# SMS_TIFS_CBASS_0_CBASS_FW_45080000h register map
Vendor: Texas Instruments
Peripheral module from a debugger description file (folder AM275x).
Registers are 32-bit, read-write, reset 0x0 unless marked. A register's access mark holds for its fields unless they carry their own. Offsets are as the file gives them; lines under a group give offsets from that group; [hi:lo] are bit positions; {n}, {i} and the like mark numbered series; 'fields as' and 'values as' point back to an identical list; <NAME> marks a mode.

## cbass_fw
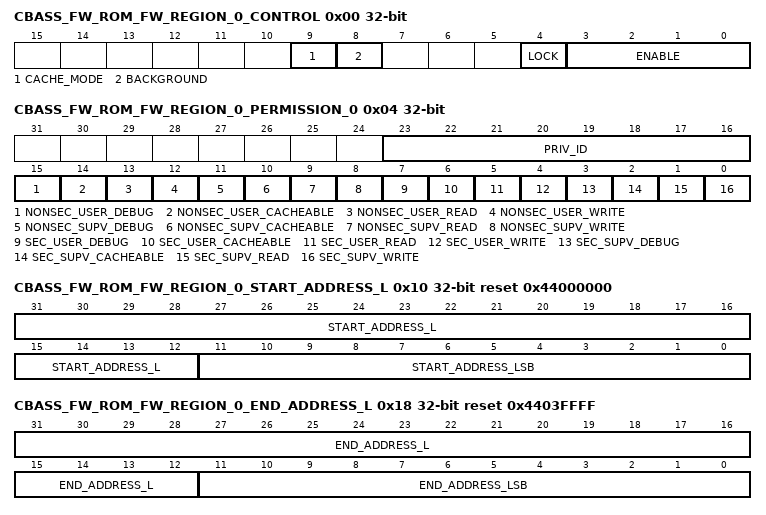
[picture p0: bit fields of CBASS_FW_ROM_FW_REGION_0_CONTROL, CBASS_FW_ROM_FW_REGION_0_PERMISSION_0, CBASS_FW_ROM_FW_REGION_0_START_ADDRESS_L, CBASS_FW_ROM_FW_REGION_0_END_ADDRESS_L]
0x00 CBASS_FW_ROM_FW_REGION_0_CONTROL access not given — The FW Region 0 Control Register defines the control fields for the target Irom.slv region 0 firewall.
  [9] CACHE_MODE rw — Cache mode for region. Set to 1 to check cache permissions. Set to 0 to ignore cache permissions. Reset Source: sms_custom_rst_mod_g_rst_n
  [8] BACKGROUND rw — Background enable for region. There can be 1 backgroun region per FW and foreground regions can have overlapping addresses only with the background region. Reset Source: sms_custom_rst_mod_g_rst_n
  [4] LOCK — Lock region. Once set region values cannot be modified. Reset Source: sms_custom_rst_mod_g_rst_n (access R/W1TS)
  [3:0] ENABLE rw — Enable region. A value of 0xA enables, others disable. Reset Source: sms_custom_rst_mod_g_rst_n
0x04 CBASS_FW_ROM_FW_REGION_0_PERMISSION_0 — The FW Region 0 Permission 0 Register defines the permissions for the target Irom.slv region 0 firewall.
  [23:16] PRIV_ID — Allowed privid. Reset Source: sms_custom_rst_mod_g_rst_n
  [15] NONSEC_USER_DEBUG — Non-secure user debug allowed. Reset Source: sms_custom_rst_mod_g_rst_n
  [14] NONSEC_USER_CACHEABLE — Non-secure user cacheable allowed. Reset Source: sms_custom_rst_mod_g_rst_n
  [13] NONSEC_USER_READ — Non-secure user read allowed. Reset Source: sms_custom_rst_mod_g_rst_n
  [12] NONSEC_USER_WRITE — Non-secure user write allowed. Reset Source: sms_custom_rst_mod_g_rst_n
  [11] NONSEC_SUPV_DEBUG — Non-secure supervisor debug allowed. Reset Source: sms_custom_rst_mod_g_rst_n
  [10] NONSEC_SUPV_CACHEABLE — Non-secure supervisor cacheable allowed. Reset Source: sms_custom_rst_mod_g_rst_n
  [9] NONSEC_SUPV_READ — Non-secure supervisor read allowed. Reset Source: sms_custom_rst_mod_g_rst_n
  [8] NONSEC_SUPV_WRITE — Non-secure supervisor write allowed. Reset Source: sms_custom_rst_mod_g_rst_n
  [7] SEC_USER_DEBUG — Secure user debug allowed. Reset Source: sms_custom_rst_mod_g_rst_n
  [6] SEC_USER_CACHEABLE — Secure user cacheable allowed. Reset Source: sms_custom_rst_mod_g_rst_n
  [5] SEC_USER_READ — Secure user read allowed. Reset Source: sms_custom_rst_mod_g_rst_n
  [4] SEC_USER_WRITE — Secure user write allowed. Reset Source: sms_custom_rst_mod_g_rst_n
  [3] SEC_SUPV_DEBUG — Secure supervisor debug allowed. Reset Source: sms_custom_rst_mod_g_rst_n
  [2] SEC_SUPV_CACHEABLE — Secure supervisor cacheable allowed. Reset Source: sms_custom_rst_mod_g_rst_n
  [1] SEC_SUPV_READ — Secure supervisor read allowed. Reset Source: sms_custom_rst_mod_g_rst_n
  [0] SEC_SUPV_WRITE — Secure supervisor write allowed. Reset Source: sms_custom_rst_mod_g_rst_n
0x10 CBASS_FW_ROM_FW_REGION_0_START_ADDRESS_L access per field reset 0x44000000 — The FW Region 0 Start Address Low Register defines the start address bits 31 to 0 for the target Irom.slv region 0 firewall.
  [31:12] START_ADDRESS_L rw — Start address bits 31 to 12. Lowest 12 bits are forced to 0 as address must be 4KB aligned. Reset Source: sms_custom_rst_mod_g_rst_n
  [11:0] START_ADDRESS_LSB ro — Start address bits 11 to 0 are forced to 0 as address must be 4KB aligned. Reset Source: sms_custom_rst_mod_g_rst_n
0x14 CBASS_FW_ROM_FW_REGION_0_START_ADDRESS_H — The FW Region 0 Start Address High Register defines the start address bits 47 to 32 for the target Irom.slv region 0 firewall.
  [15:0] START_ADDRESS_H — Start address bits 47 to 32. Reset Source: sms_custom_rst_mod_g_rst_n
0x18 CBASS_FW_ROM_FW_REGION_0_END_ADDRESS_L access per field reset 0x4403FFFF — The FW Region 0 End Address Low Register defines the end address bits 31 to 0 to include for the target Irom.slv region 0 firewall.
  [31:12] END_ADDRESS_L rw — End address bits 31 to 12 to include in the match. Lowest 12 bits are forced to 1s as address must be 4KB aligned. Reset Source: sms_custom_rst_mod_g_rst_n
  [11:0] END_ADDRESS_LSB ro — End address bits 11 to 0 are forced to 1s as address must be 4KB aligned minus 1. Reset Source: sms_custom_rst_mod_g_rst_n
0x1C CBASS_FW_ROM_FW_REGION_0_END_ADDRESS_H — The FW Region 0 End Address High Register defines the end address bits 47 to 32 to include for the target Irom.slv region 0 firewall.
  [15:0] END_ADDRESS_H — End address bits 47 to 32 to include in the match. Reset Source: sms_custom_rst_mod_g_rst_n
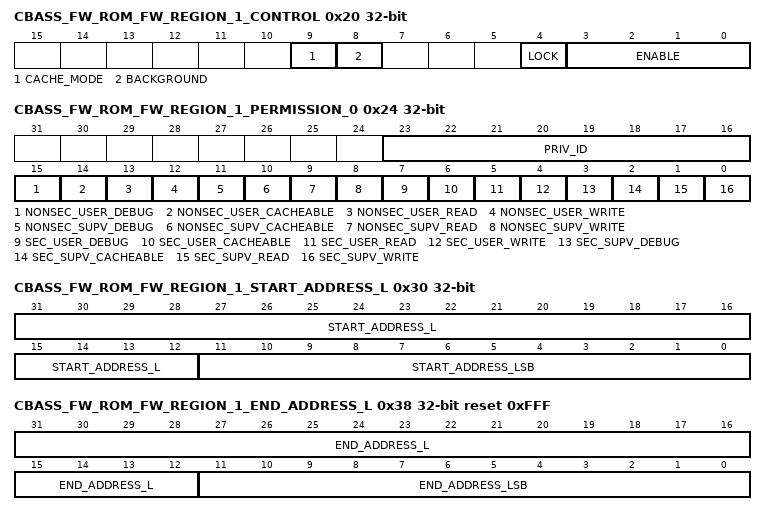
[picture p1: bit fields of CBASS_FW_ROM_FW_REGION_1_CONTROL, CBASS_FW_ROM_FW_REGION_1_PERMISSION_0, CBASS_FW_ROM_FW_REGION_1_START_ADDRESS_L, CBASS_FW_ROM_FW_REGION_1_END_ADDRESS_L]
0x20 CBASS_FW_ROM_FW_REGION_1_CONTROL access not given — The FW Region 1 Control Register defines the control fields for the target Irom.slv region 1 firewall.
  fields as CBASS_FW_ROM_FW_REGION_0_CONTROL
0x24 CBASS_FW_ROM_FW_REGION_1_PERMISSION_0 — The FW Region 1 Permission 0 Register defines the permissions for the target Irom.slv region 1 firewall.
  fields as CBASS_FW_ROM_FW_REGION_0_PERMISSION_0
0x30 CBASS_FW_ROM_FW_REGION_1_START_ADDRESS_L access per field — The FW Region 1 Start Address Low Register defines the start address bits 31 to 0 for the target Irom.slv region 1 firewall.
  fields as CBASS_FW_ROM_FW_REGION_0_START_ADDRESS_L
0x34 CBASS_FW_ROM_FW_REGION_1_START_ADDRESS_H — The FW Region 1 Start Address High Register defines the start address bits 47 to 32 for the target Irom.slv region 1 firewall.
  fields as CBASS_FW_ROM_FW_REGION_0_START_ADDRESS_H
0x38 CBASS_FW_ROM_FW_REGION_1_END_ADDRESS_L access per field reset 0xFFF — The FW Region 1 End Address Low Register defines the end address bits 31 to 0 to include for the target Irom.slv region 1 firewall.
  fields as CBASS_FW_ROM_FW_REGION_0_END_ADDRESS_L
0x3C CBASS_FW_ROM_FW_REGION_1_END_ADDRESS_H — The FW Region 1 End Address High Register defines the end address bits 47 to 32 to include for the target Irom.slv region 1 firewall.
  fields as CBASS_FW_ROM_FW_REGION_0_END_ADDRESS_H
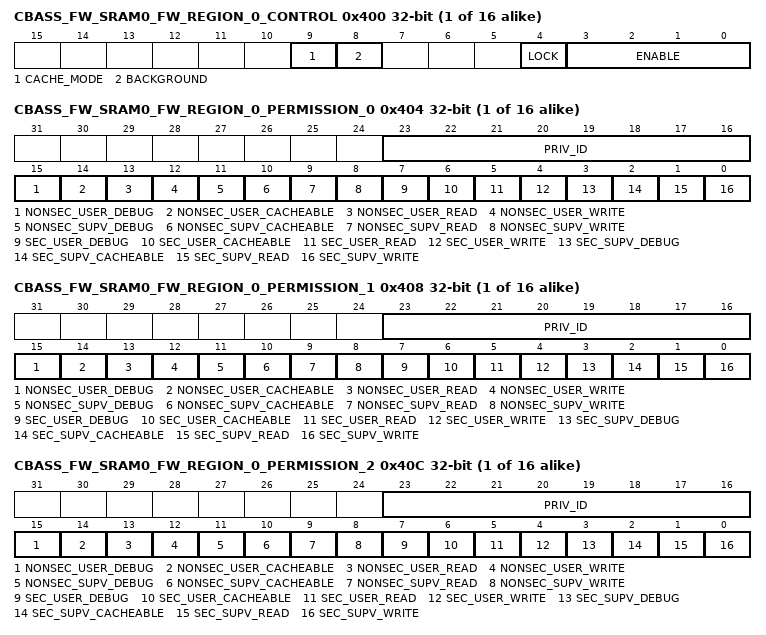
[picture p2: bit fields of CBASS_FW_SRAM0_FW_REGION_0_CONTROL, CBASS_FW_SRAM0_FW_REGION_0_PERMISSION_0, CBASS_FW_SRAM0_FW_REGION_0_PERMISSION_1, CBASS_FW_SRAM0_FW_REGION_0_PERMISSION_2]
{0x400+0x20*i} CBASS_FW_SRAM0_FW_REGION_{i}_CONTROL access not given (i=0..15) — The FW Region {i} Control Register defines the control fields for the target Isram0.slv region {i} firewall.
  fields as CBASS_FW_ROM_FW_REGION_0_CONTROL
{0x404+0x20*i} CBASS_FW_SRAM0_FW_REGION_{i}_PERMISSION_0 (i=0..15) — The FW Region {i} Permission 0 Register defines the permissions for the target Isram0.slv region {i} firewall.
  fields as CBASS_FW_ROM_FW_REGION_0_PERMISSION_0
{0x408+0x20*i} CBASS_FW_SRAM0_FW_REGION_{i}_PERMISSION_1 (i=0..15) — The FW Region {i} Permission 1 Register defines the permissions for the target Isram0.slv region {i} firewall.
  fields as CBASS_FW_ROM_FW_REGION_0_PERMISSION_0
{0x40C+0x20*i} CBASS_FW_SRAM0_FW_REGION_{i}_PERMISSION_2 (i=0..15) — The FW Region {i} Permission 2 Register defines the permissions for the target Isram0.slv region {i} firewall.
  fields as CBASS_FW_ROM_FW_REGION_0_PERMISSION_0
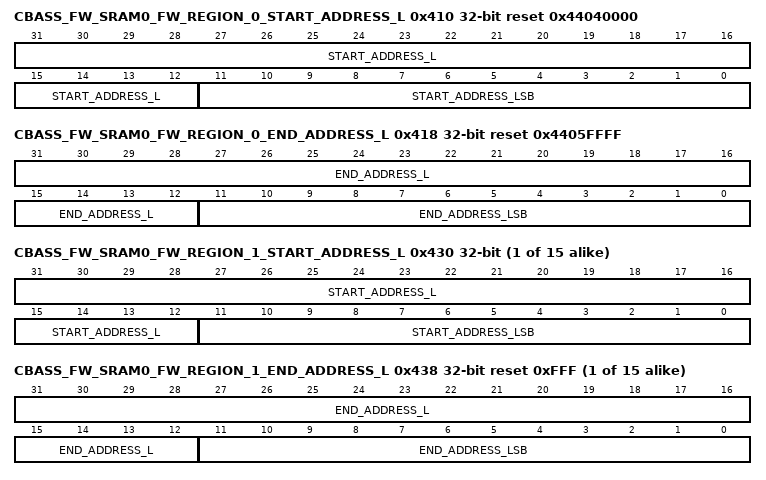
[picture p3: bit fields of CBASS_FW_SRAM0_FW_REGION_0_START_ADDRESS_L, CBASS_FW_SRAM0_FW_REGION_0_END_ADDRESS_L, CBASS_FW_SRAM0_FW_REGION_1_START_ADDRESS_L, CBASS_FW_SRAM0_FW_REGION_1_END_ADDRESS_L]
0x410 CBASS_FW_SRAM0_FW_REGION_0_START_ADDRESS_L access per field reset 0x44040000 — The FW Region 0 Start Address Low Register defines the start address bits 31 to 0 for the target Isram0.slv region 0 firewall.
  fields as CBASS_FW_ROM_FW_REGION_0_START_ADDRESS_L
{0x414+0x20*i} CBASS_FW_SRAM0_FW_REGION_{i}_START_ADDRESS_H (i=0..15) — The FW Region {i} Start Address High Register defines the start address bits 47 to 32 for the target Isram0.slv region {i} firewall.
  fields as CBASS_FW_ROM_FW_REGION_0_START_ADDRESS_H
0x418 CBASS_FW_SRAM0_FW_REGION_0_END_ADDRESS_L access per field reset 0x4405FFFF — The FW Region 0 End Address Low Register defines the end address bits 31 to 0 to include for the target Isram0.slv region 0 firewall.
  fields as CBASS_FW_ROM_FW_REGION_0_END_ADDRESS_L
{0x41C+0x20*i} CBASS_FW_SRAM0_FW_REGION_{i}_END_ADDRESS_H (i=0..15) — The FW Region {i} End Address High Register defines the end address bits 47 to 32 to include for the target Isram0.slv region {i} firewall.
  fields as CBASS_FW_ROM_FW_REGION_0_END_ADDRESS_H
{0x410+0x20*i} CBASS_FW_SRAM0_FW_REGION_{i}_START_ADDRESS_L access per field (i=1..15) — The FW Region {i} Start Address Low Register defines the start address bits 31 to 0 for the target Isram0.slv region {i} firewall.
  fields as CBASS_FW_ROM_FW_REGION_0_START_ADDRESS_L
{0x418+0x20*i} CBASS_FW_SRAM0_FW_REGION_{i}_END_ADDRESS_L access per field reset 0xFFF (i=1..15) — The FW Region {i} End Address Low Register defines the end address bits 31 to 0 to include for the target Isram0.slv region {i} firewall.
  fields as CBASS_FW_ROM_FW_REGION_0_END_ADDRESS_L
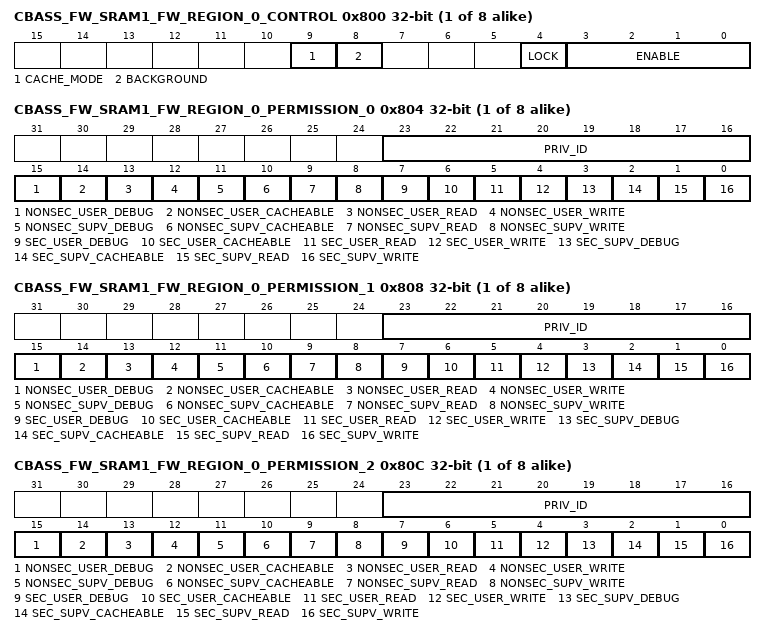
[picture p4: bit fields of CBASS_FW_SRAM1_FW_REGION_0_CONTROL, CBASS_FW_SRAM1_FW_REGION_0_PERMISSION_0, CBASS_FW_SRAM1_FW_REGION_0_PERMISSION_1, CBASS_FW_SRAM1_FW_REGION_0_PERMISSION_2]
{0x800+0x20*i} CBASS_FW_SRAM1_FW_REGION_{i}_CONTROL access not given (i=0..7) — The FW Region {i} Control Register defines the control fields for the target Isram1.slv region {i} firewall.
  fields as CBASS_FW_ROM_FW_REGION_0_CONTROL
{0x804+0x20*i} CBASS_FW_SRAM1_FW_REGION_{i}_PERMISSION_0 (i=0..7) — The FW Region {i} Permission 0 Register defines the permissions for the target Isram1.slv region {i} firewall.
  fields as CBASS_FW_ROM_FW_REGION_0_PERMISSION_0
{0x808+0x20*i} CBASS_FW_SRAM1_FW_REGION_{i}_PERMISSION_1 (i=0..7) — The FW Region {i} Permission 1 Register defines the permissions for the target Isram1.slv region {i} firewall.
  fields as CBASS_FW_ROM_FW_REGION_0_PERMISSION_0
{0x80C+0x20*i} CBASS_FW_SRAM1_FW_REGION_{i}_PERMISSION_2 (i=0..7) — The FW Region {i} Permission 2 Register defines the permissions for the target Isram1.slv region {i} firewall.
  fields as CBASS_FW_ROM_FW_REGION_0_PERMISSION_0
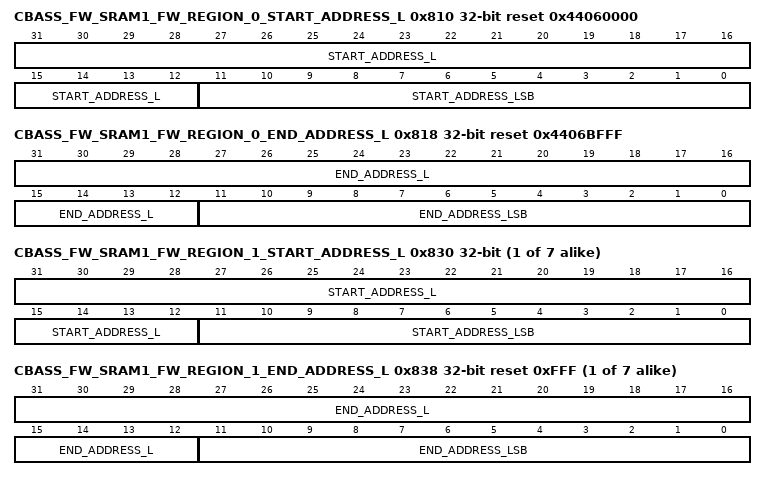
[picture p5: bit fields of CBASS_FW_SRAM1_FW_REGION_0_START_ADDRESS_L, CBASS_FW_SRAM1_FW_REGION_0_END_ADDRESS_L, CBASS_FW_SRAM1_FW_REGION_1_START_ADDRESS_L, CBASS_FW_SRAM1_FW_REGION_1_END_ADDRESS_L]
0x810 CBASS_FW_SRAM1_FW_REGION_0_START_ADDRESS_L access per field reset 0x44060000 — The FW Region 0 Start Address Low Register defines the start address bits 31 to 0 for the target Isram1.slv region 0 firewall.
  fields as CBASS_FW_ROM_FW_REGION_0_START_ADDRESS_L
{0x814+0x20*i} CBASS_FW_SRAM1_FW_REGION_{i}_START_ADDRESS_H (i=0..7) — The FW Region {i} Start Address High Register defines the start address bits 47 to 32 for the target Isram1.slv region {i} firewall.
  fields as CBASS_FW_ROM_FW_REGION_0_START_ADDRESS_H
0x818 CBASS_FW_SRAM1_FW_REGION_0_END_ADDRESS_L access per field reset 0x4406BFFF — The FW Region 0 End Address Low Register defines the end address bits 31 to 0 to include for the target Isram1.slv region 0 firewall.
  fields as CBASS_FW_ROM_FW_REGION_0_END_ADDRESS_L
{0x81C+0x20*i} CBASS_FW_SRAM1_FW_REGION_{i}_END_ADDRESS_H (i=0..7) — The FW Region {i} End Address High Register defines the end address bits 47 to 32 to include for the target Isram1.slv region {i} firewall.
  fields as CBASS_FW_ROM_FW_REGION_0_END_ADDRESS_H
{0x810+0x20*i} CBASS_FW_SRAM1_FW_REGION_{i}_START_ADDRESS_L access per field (i=1..7) — The FW Region {i} Start Address Low Register defines the start address bits 31 to 0 for the target Isram1.slv region {i} firewall.
  fields as CBASS_FW_ROM_FW_REGION_0_START_ADDRESS_L
{0x818+0x20*i} CBASS_FW_SRAM1_FW_REGION_{i}_END_ADDRESS_L access per field reset 0xFFF (i=1..7) — The FW Region {i} End Address Low Register defines the end address bits 31 to 0 to include for the target Isram1.slv region {i} firewall.
  fields as CBASS_FW_ROM_FW_REGION_0_END_ADDRESS_L
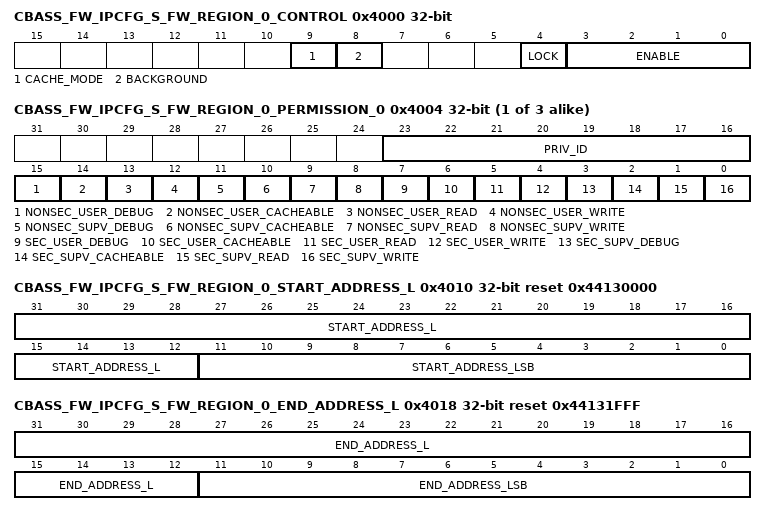
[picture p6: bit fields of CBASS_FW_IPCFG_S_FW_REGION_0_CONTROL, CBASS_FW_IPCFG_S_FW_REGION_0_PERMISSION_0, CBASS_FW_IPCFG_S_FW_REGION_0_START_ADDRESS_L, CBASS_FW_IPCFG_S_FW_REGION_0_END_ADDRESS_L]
0x4000 CBASS_FW_IPCFG_S_FW_REGION_0_CONTROL access not given — The FW Region 0 Control Register defines the control fields for the target Ipcfg.slv region 0 firewall.
  fields as CBASS_FW_ROM_FW_REGION_0_CONTROL
{0x4004+4i} CBASS_FW_IPCFG_S_FW_REGION_0_PERMISSION_{i} (i=0..2) — The FW Region 0 Permission {i} Register defines the permissions for the target Ipcfg.slv region 0 firewall.
  fields as CBASS_FW_ROM_FW_REGION_0_PERMISSION_0
0x4010 CBASS_FW_IPCFG_S_FW_REGION_0_START_ADDRESS_L access per field reset 0x44130000 — The FW Region 0 Start Address Low Register defines the start address bits 31 to 0 for the target Ipcfg.slv region 0 firewall.
  fields as CBASS_FW_ROM_FW_REGION_0_START_ADDRESS_L
0x4014 CBASS_FW_IPCFG_S_FW_REGION_0_START_ADDRESS_H — The FW Region 0 Start Address High Register defines the start address bits 47 to 32 for the target Ipcfg.slv region 0 firewall.
  fields as CBASS_FW_ROM_FW_REGION_0_START_ADDRESS_H
0x4018 CBASS_FW_IPCFG_S_FW_REGION_0_END_ADDRESS_L access per field reset 0x44131FFF — The FW Region 0 End Address Low Register defines the end address bits 31 to 0 to include for the target Ipcfg.slv region 0 firewall.
  fields as CBASS_FW_ROM_FW_REGION_0_END_ADDRESS_L
0x401C CBASS_FW_IPCFG_S_FW_REGION_0_END_ADDRESS_H — The FW Region 0 End Address High Register defines the end address bits 47 to 32 to include for the target Ipcfg.slv region 0 firewall.
  fields as CBASS_FW_ROM_FW_REGION_0_END_ADDRESS_H
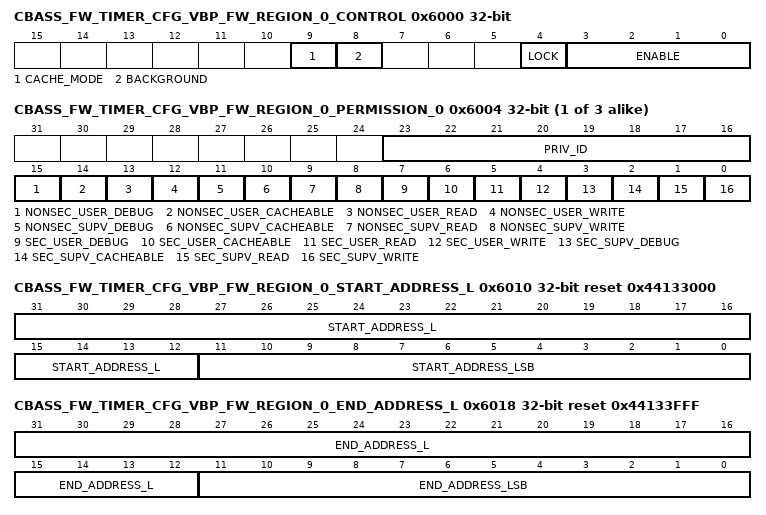
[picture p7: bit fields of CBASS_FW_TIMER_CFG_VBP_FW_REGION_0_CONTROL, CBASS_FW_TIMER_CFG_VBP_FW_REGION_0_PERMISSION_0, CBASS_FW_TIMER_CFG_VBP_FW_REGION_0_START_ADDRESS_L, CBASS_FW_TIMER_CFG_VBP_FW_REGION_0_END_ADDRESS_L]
0x6000 CBASS_FW_TIMER_CFG_VBP_FW_REGION_0_CONTROL access not given — The FW Region 0 Control Register defines the control fields for the target Itimer1.timer_cfg_vbp region 0 firewall.
  fields as CBASS_FW_ROM_FW_REGION_0_CONTROL
{0x6004+4i} CBASS_FW_TIMER_CFG_VBP_FW_REGION_0_PERMISSION_{i} (i=0..2) — The FW Region 0 Permission {i} Register defines the permissions for the target Itimer1.timer_cfg_vbp region 0 firewall.
  fields as CBASS_FW_ROM_FW_REGION_0_PERMISSION_0
0x6010 CBASS_FW_TIMER_CFG_VBP_FW_REGION_0_START_ADDRESS_L access per field reset 0x44133000 — The FW Region 0 Start Address Low Register defines the start address bits 31 to 0 for the target Itimer1.timer_cfg_vbp region 0 firewall.
  fields as CBASS_FW_ROM_FW_REGION_0_START_ADDRESS_L
0x6014 CBASS_FW_TIMER_CFG_VBP_FW_REGION_0_START_ADDRESS_H — The FW Region 0 Start Address High Register defines the start address bits 47 to 32 for the target Itimer1.timer_cfg_vbp region 0 firewall.
  fields as CBASS_FW_ROM_FW_REGION_0_START_ADDRESS_H
0x6018 CBASS_FW_TIMER_CFG_VBP_FW_REGION_0_END_ADDRESS_L access per field reset 0x44133FFF — The FW Region 0 End Address Low Register defines the end address bits 31 to 0 to include for the target Itimer1.timer_cfg_vbp region 0 firewall.
  fields as CBASS_FW_ROM_FW_REGION_0_END_ADDRESS_L
0x601C CBASS_FW_TIMER_CFG_VBP_FW_REGION_0_END_ADDRESS_H — The FW Region 0 End Address High Register defines the end address bits 47 to 32 to include for the target Itimer1.timer_cfg_vbp region 0 firewall.
  fields as CBASS_FW_ROM_FW_REGION_0_END_ADDRESS_H
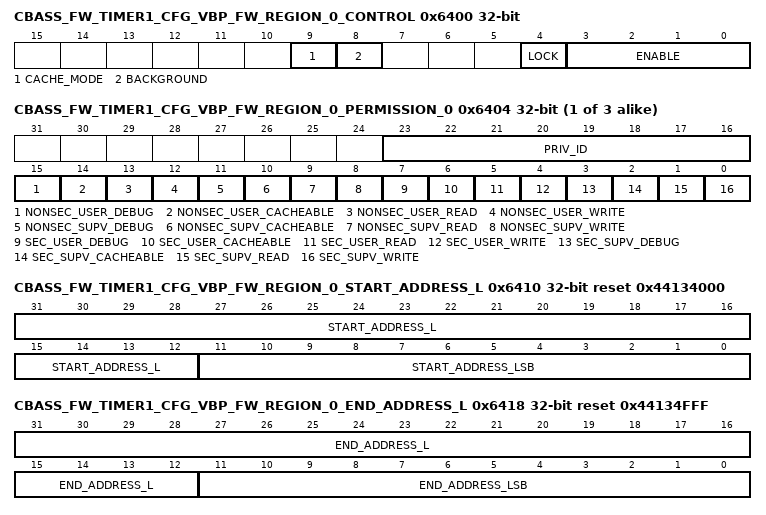
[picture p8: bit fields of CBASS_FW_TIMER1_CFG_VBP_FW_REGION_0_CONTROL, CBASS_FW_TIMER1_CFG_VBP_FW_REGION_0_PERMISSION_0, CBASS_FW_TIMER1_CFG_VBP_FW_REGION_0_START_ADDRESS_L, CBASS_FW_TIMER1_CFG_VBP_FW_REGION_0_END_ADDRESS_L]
0x6400 CBASS_FW_TIMER1_CFG_VBP_FW_REGION_0_CONTROL access not given — The FW Region 0 Control Register defines the control fields for the target Itimer2.timer_cfg_vbp region 0 firewall.
  fields as CBASS_FW_ROM_FW_REGION_0_CONTROL
{0x6404+4i} CBASS_FW_TIMER1_CFG_VBP_FW_REGION_0_PERMISSION_{i} (i=0..2) — The FW Region 0 Permission {i} Register defines the permissions for the target Itimer2.timer_cfg_vbp region 0 firewall.
  fields as CBASS_FW_ROM_FW_REGION_0_PERMISSION_0
0x6410 CBASS_FW_TIMER1_CFG_VBP_FW_REGION_0_START_ADDRESS_L access per field reset 0x44134000 — The FW Region 0 Start Address Low Register defines the start address bits 31 to 0 for the target Itimer2.timer_cfg_vbp region 0 firewall.
  fields as CBASS_FW_ROM_FW_REGION_0_START_ADDRESS_L
0x6414 CBASS_FW_TIMER1_CFG_VBP_FW_REGION_0_START_ADDRESS_H — The FW Region 0 Start Address High Register defines the start address bits 47 to 32 for the target Itimer2.timer_cfg_vbp region 0 firewall.
  fields as CBASS_FW_ROM_FW_REGION_0_START_ADDRESS_H
0x6418 CBASS_FW_TIMER1_CFG_VBP_FW_REGION_0_END_ADDRESS_L access per field reset 0x44134FFF — The FW Region 0 End Address Low Register defines the end address bits 31 to 0 to include for the target Itimer2.timer_cfg_vbp region 0 firewall.
  fields as CBASS_FW_ROM_FW_REGION_0_END_ADDRESS_L
0x641C CBASS_FW_TIMER1_CFG_VBP_FW_REGION_0_END_ADDRESS_H — The FW Region 0 End Address High Register defines the end address bits 47 to 32 to include for the target Itimer2.timer_cfg_vbp region 0 firewall.
  fields as CBASS_FW_ROM_FW_REGION_0_END_ADDRESS_H
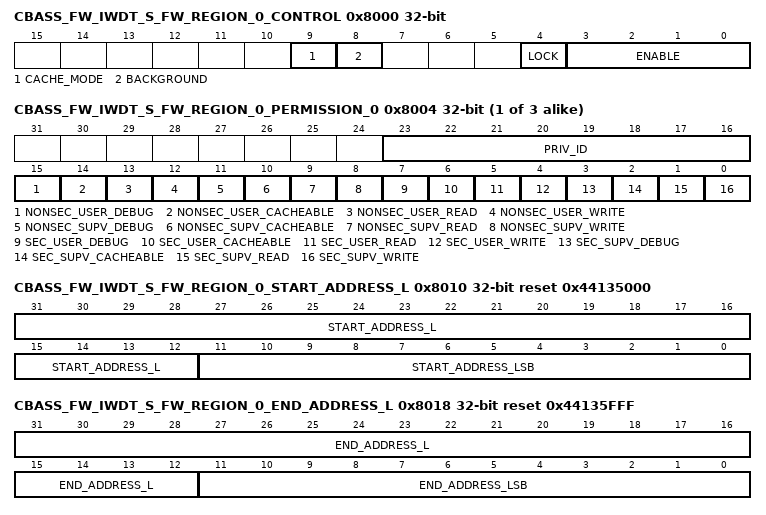
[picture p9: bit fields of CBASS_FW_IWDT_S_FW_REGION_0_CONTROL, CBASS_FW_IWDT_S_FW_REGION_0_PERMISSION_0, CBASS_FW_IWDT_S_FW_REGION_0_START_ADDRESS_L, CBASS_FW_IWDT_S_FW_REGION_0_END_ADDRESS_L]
0x8000 CBASS_FW_IWDT_S_FW_REGION_0_CONTROL access not given — The FW Region 0 Control Register defines the control fields for the target Iwdt.slv region 0 firewall.
  fields as CBASS_FW_ROM_FW_REGION_0_CONTROL
{0x8004+4i} CBASS_FW_IWDT_S_FW_REGION_0_PERMISSION_{i} (i=0..2) — The FW Region 0 Permission {i} Register defines the permissions for the target Iwdt.slv region 0 firewall.
  fields as CBASS_FW_ROM_FW_REGION_0_PERMISSION_0
0x8010 CBASS_FW_IWDT_S_FW_REGION_0_START_ADDRESS_L access per field reset 0x44135000 — The FW Region 0 Start Address Low Register defines the start address bits 31 to 0 for the target Iwdt.slv region 0 firewall.
  fields as CBASS_FW_ROM_FW_REGION_0_START_ADDRESS_L
0x8014 CBASS_FW_IWDT_S_FW_REGION_0_START_ADDRESS_H — The FW Region 0 Start Address High Register defines the start address bits 47 to 32 for the target Iwdt.slv region 0 firewall.
  fields as CBASS_FW_ROM_FW_REGION_0_START_ADDRESS_H
0x8018 CBASS_FW_IWDT_S_FW_REGION_0_END_ADDRESS_L access per field reset 0x44135FFF — The FW Region 0 End Address Low Register defines the end address bits 31 to 0 to include for the target Iwdt.slv region 0 firewall.
  fields as CBASS_FW_ROM_FW_REGION_0_END_ADDRESS_L
0x801C CBASS_FW_IWDT_S_FW_REGION_0_END_ADDRESS_H — The FW Region 0 End Address High Register defines the end address bits 47 to 32 to include for the target Iwdt.slv region 0 firewall.
  fields as CBASS_FW_ROM_FW_REGION_0_END_ADDRESS_H
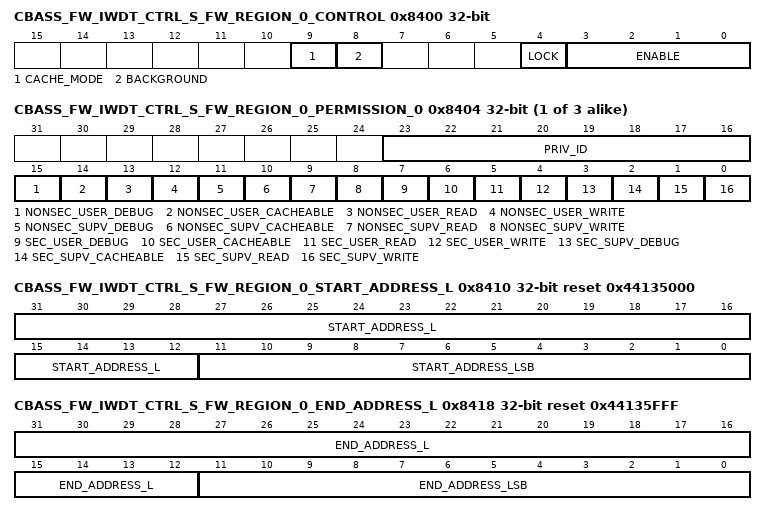
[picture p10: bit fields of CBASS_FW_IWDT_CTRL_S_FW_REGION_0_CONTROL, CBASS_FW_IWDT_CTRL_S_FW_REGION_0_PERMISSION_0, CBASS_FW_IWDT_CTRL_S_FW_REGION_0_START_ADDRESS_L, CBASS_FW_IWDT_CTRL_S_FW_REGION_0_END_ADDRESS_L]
0x8400 CBASS_FW_IWDT_CTRL_S_FW_REGION_0_CONTROL access not given — The FW Region 0 Control Register defines the control fields for the target Iwdt_ctrl.slv region 0 firewall.
  fields as CBASS_FW_ROM_FW_REGION_0_CONTROL
{0x8404+4i} CBASS_FW_IWDT_CTRL_S_FW_REGION_0_PERMISSION_{i} (i=0..2) — The FW Region 0 Permission {i} Register defines the permissions for the target Iwdt_ctrl.slv region 0 firewall.
  fields as CBASS_FW_ROM_FW_REGION_0_PERMISSION_0
0x8410 CBASS_FW_IWDT_CTRL_S_FW_REGION_0_START_ADDRESS_L access per field reset 0x44135000 — The FW Region 0 Start Address Low Register defines the start address bits 31 to 0 for the target Iwdt_ctrl.slv region 0 firewall.
  fields as CBASS_FW_ROM_FW_REGION_0_START_ADDRESS_L
0x8414 CBASS_FW_IWDT_CTRL_S_FW_REGION_0_START_ADDRESS_H — The FW Region 0 Start Address High Register defines the start address bits 47 to 32 for the target Iwdt_ctrl.slv region 0 firewall.
  fields as CBASS_FW_ROM_FW_REGION_0_START_ADDRESS_H
0x8418 CBASS_FW_IWDT_CTRL_S_FW_REGION_0_END_ADDRESS_L access per field reset 0x44135FFF — The FW Region 0 End Address Low Register defines the end address bits 31 to 0 to include for the target Iwdt_ctrl.slv region 0 firewall.
  fields as CBASS_FW_ROM_FW_REGION_0_END_ADDRESS_L
0x841C CBASS_FW_IWDT_CTRL_S_FW_REGION_0_END_ADDRESS_H — The FW Region 0 End Address High Register defines the end address bits 47 to 32 to include for the target Iwdt_ctrl.slv region 0 firewall.
  fields as CBASS_FW_ROM_FW_REGION_0_END_ADDRESS_H
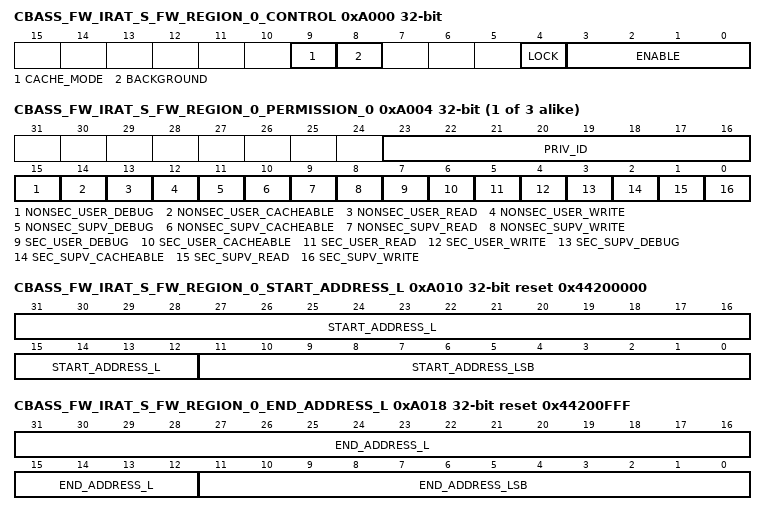
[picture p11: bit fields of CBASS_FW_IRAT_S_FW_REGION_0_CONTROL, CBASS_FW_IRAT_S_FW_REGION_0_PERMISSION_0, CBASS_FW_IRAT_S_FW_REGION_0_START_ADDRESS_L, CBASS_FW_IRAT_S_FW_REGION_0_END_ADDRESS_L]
0xA000 CBASS_FW_IRAT_S_FW_REGION_0_CONTROL access not given — The FW Region 0 Control Register defines the control fields for the target Irat.slv region 0 firewall.
  fields as CBASS_FW_ROM_FW_REGION_0_CONTROL
{0xA004+4i} CBASS_FW_IRAT_S_FW_REGION_0_PERMISSION_{i} (i=0..2) — The FW Region 0 Permission {i} Register defines the permissions for the target Irat.slv region 0 firewall.
  fields as CBASS_FW_ROM_FW_REGION_0_PERMISSION_0
0xA010 CBASS_FW_IRAT_S_FW_REGION_0_START_ADDRESS_L access per field reset 0x44200000 — The FW Region 0 Start Address Low Register defines the start address bits 31 to 0 for the target Irat.slv region 0 firewall.
  fields as CBASS_FW_ROM_FW_REGION_0_START_ADDRESS_L
0xA014 CBASS_FW_IRAT_S_FW_REGION_0_START_ADDRESS_H — The FW Region 0 Start Address High Register defines the start address bits 47 to 32 for the target Irat.slv region 0 firewall.
  fields as CBASS_FW_ROM_FW_REGION_0_START_ADDRESS_H
0xA018 CBASS_FW_IRAT_S_FW_REGION_0_END_ADDRESS_L access per field reset 0x44200FFF — The FW Region 0 End Address Low Register defines the end address bits 31 to 0 to include for the target Irat.slv region 0 firewall.
  fields as CBASS_FW_ROM_FW_REGION_0_END_ADDRESS_L
0xA01C CBASS_FW_IRAT_S_FW_REGION_0_END_ADDRESS_H — The FW Region 0 End Address High Register defines the end address bits 47 to 32 to include for the target Irat.slv region 0 firewall.
  fields as CBASS_FW_ROM_FW_REGION_0_END_ADDRESS_H
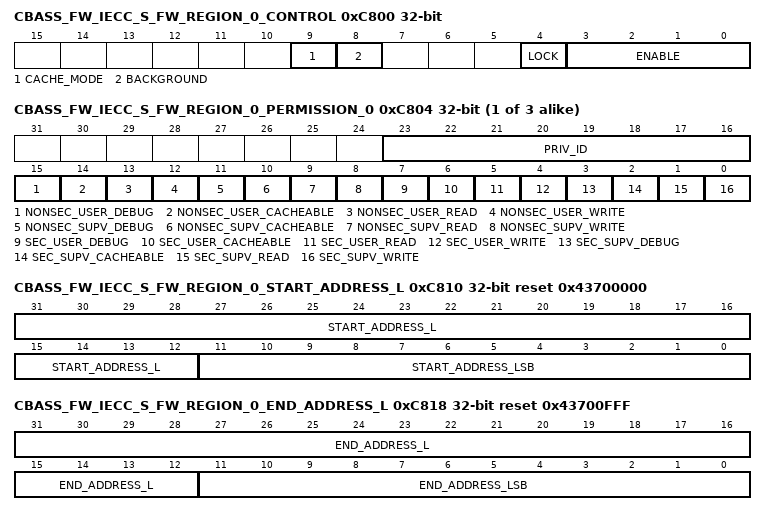
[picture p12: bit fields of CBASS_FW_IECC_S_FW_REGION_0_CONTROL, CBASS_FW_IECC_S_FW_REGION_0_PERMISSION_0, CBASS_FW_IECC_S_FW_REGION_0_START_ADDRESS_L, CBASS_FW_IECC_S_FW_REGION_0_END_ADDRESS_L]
0xC800 CBASS_FW_IECC_S_FW_REGION_0_CONTROL access not given — The FW Region 0 Control Register defines the control fields for the target Iecc.cfg region 0 firewall.
  fields as CBASS_FW_ROM_FW_REGION_0_CONTROL
{0xC804+4i} CBASS_FW_IECC_S_FW_REGION_0_PERMISSION_{i} (i=0..2) — The FW Region 0 Permission {i} Register defines the permissions for the target Iecc.cfg region 0 firewall.
  fields as CBASS_FW_ROM_FW_REGION_0_PERMISSION_0
0xC810 CBASS_FW_IECC_S_FW_REGION_0_START_ADDRESS_L access per field reset 0x43700000 — The FW Region 0 Start Address Low Register defines the start address bits 31 to 0 for the target Iecc.cfg region 0 firewall.
  fields as CBASS_FW_ROM_FW_REGION_0_START_ADDRESS_L
0xC814 CBASS_FW_IECC_S_FW_REGION_0_START_ADDRESS_H — The FW Region 0 Start Address High Register defines the start address bits 47 to 32 for the target Iecc.cfg region 0 firewall.
  fields as CBASS_FW_ROM_FW_REGION_0_START_ADDRESS_H
0xC818 CBASS_FW_IECC_S_FW_REGION_0_END_ADDRESS_L access per field reset 0x43700FFF — The FW Region 0 End Address Low Register defines the end address bits 31 to 0 to include for the target Iecc.cfg region 0 firewall.
  fields as CBASS_FW_ROM_FW_REGION_0_END_ADDRESS_L
0xC81C CBASS_FW_IECC_S_FW_REGION_0_END_ADDRESS_H — The FW Region 0 End Address High Register defines the end address bits 47 to 32 to include for the target Iecc.cfg region 0 firewall.
  fields as CBASS_FW_ROM_FW_REGION_0_END_ADDRESS_H
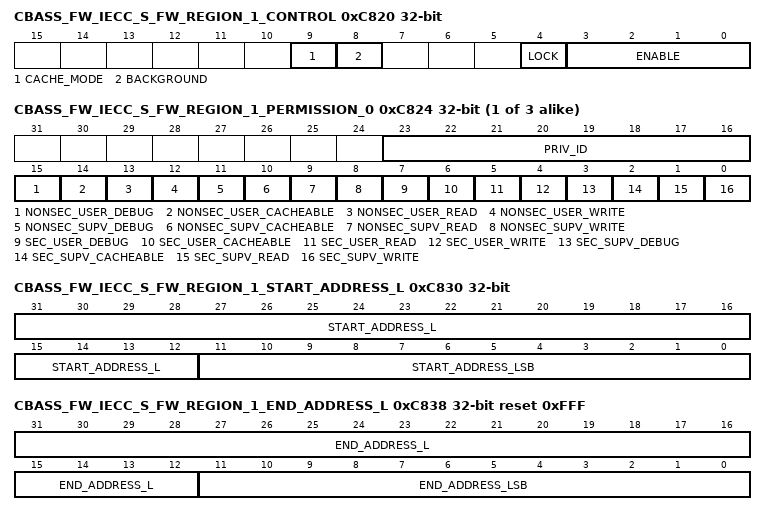
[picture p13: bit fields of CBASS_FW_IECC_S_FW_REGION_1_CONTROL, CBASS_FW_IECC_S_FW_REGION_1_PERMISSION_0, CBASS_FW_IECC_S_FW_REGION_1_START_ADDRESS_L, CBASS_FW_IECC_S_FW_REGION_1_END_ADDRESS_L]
0xC820 CBASS_FW_IECC_S_FW_REGION_1_CONTROL access not given — The FW Region 1 Control Register defines the control fields for the target Iecc.cfg region 1 firewall.
  fields as CBASS_FW_ROM_FW_REGION_0_CONTROL
{0xC824+4i} CBASS_FW_IECC_S_FW_REGION_1_PERMISSION_{i} (i=0..2) — The FW Region 1 Permission {i} Register defines the permissions for the target Iecc.cfg region 1 firewall.
  fields as CBASS_FW_ROM_FW_REGION_0_PERMISSION_0
0xC830 CBASS_FW_IECC_S_FW_REGION_1_START_ADDRESS_L access per field — The FW Region 1 Start Address Low Register defines the start address bits 31 to 0 for the target Iecc.cfg region 1 firewall.
  fields as CBASS_FW_ROM_FW_REGION_0_START_ADDRESS_L
0xC834 CBASS_FW_IECC_S_FW_REGION_1_START_ADDRESS_H — The FW Region 1 Start Address High Register defines the start address bits 47 to 32 for the target Iecc.cfg region 1 firewall.
  fields as CBASS_FW_ROM_FW_REGION_0_START_ADDRESS_H
0xC838 CBASS_FW_IECC_S_FW_REGION_1_END_ADDRESS_L access per field reset 0xFFF — The FW Region 1 End Address Low Register defines the end address bits 31 to 0 to include for the target Iecc.cfg region 1 firewall.
  fields as CBASS_FW_ROM_FW_REGION_0_END_ADDRESS_L
0xC83C CBASS_FW_IECC_S_FW_REGION_1_END_ADDRESS_H — The FW Region 1 End Address High Register defines the end address bits 47 to 32 to include for the target Iecc.cfg region 1 firewall.
  fields as CBASS_FW_ROM_FW_REGION_0_END_ADDRESS_H
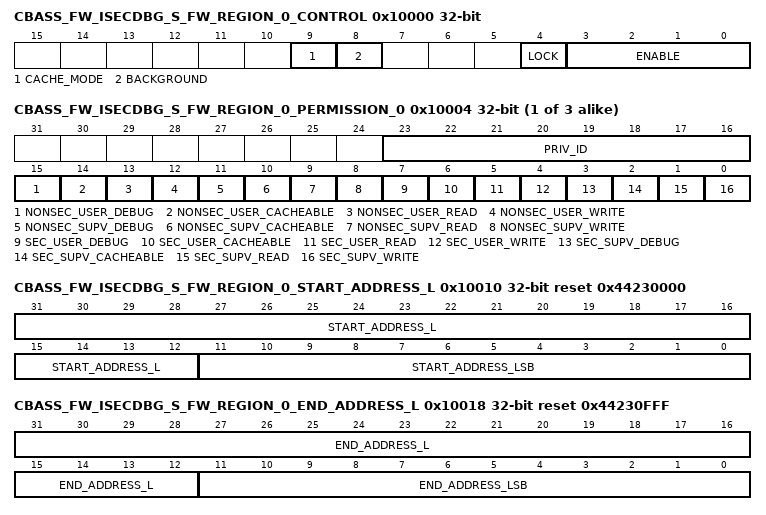
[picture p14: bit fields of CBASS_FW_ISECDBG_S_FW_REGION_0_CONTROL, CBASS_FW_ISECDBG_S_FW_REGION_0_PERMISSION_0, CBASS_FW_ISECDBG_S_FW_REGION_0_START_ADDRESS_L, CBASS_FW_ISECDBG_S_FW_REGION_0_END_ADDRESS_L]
0x10000 CBASS_FW_ISECDBG_S_FW_REGION_0_CONTROL access not given — The FW Region 0 Control Register defines the control fields for the target Isecdbg.slv region 0 firewall.
  fields as CBASS_FW_ROM_FW_REGION_0_CONTROL
{0x10004+4i} CBASS_FW_ISECDBG_S_FW_REGION_0_PERMISSION_{i} (i=0..2) — The FW Region 0 Permission {i} Register defines the permissions for the target Isecdbg.slv region 0 firewall.
  fields as CBASS_FW_ROM_FW_REGION_0_PERMISSION_0
0x10010 CBASS_FW_ISECDBG_S_FW_REGION_0_START_ADDRESS_L access per field reset 0x44230000 — The FW Region 0 Start Address Low Register defines the start address bits 31 to 0 for the target Isecdbg.slv region 0 firewall.
  fields as CBASS_FW_ROM_FW_REGION_0_START_ADDRESS_L
0x10014 CBASS_FW_ISECDBG_S_FW_REGION_0_START_ADDRESS_H — The FW Region 0 Start Address High Register defines the start address bits 47 to 32 for the target Isecdbg.slv region 0 firewall.
  fields as CBASS_FW_ROM_FW_REGION_0_START_ADDRESS_H
0x10018 CBASS_FW_ISECDBG_S_FW_REGION_0_END_ADDRESS_L access per field reset 0x44230FFF — The FW Region 0 End Address Low Register defines the end address bits 31 to 0 to include for the target Isecdbg.slv region 0 firewall.
  fields as CBASS_FW_ROM_FW_REGION_0_END_ADDRESS_L
0x1001C CBASS_FW_ISECDBG_S_FW_REGION_0_END_ADDRESS_H — The FW Region 0 End Address High Register defines the end address bits 47 to 32 to include for the target Isecdbg.slv region 0 firewall.
  fields as CBASS_FW_ROM_FW_REGION_0_END_ADDRESS_H
0x10800 CBASS_FW_IDBG_AUTH_S_FW_REGION_0_CONTROL access not given — The FW Region 0 Control Register defines the control fields for the target Idbg_auth.slv region 0 firewall.
  fields as CBASS_FW_ROM_FW_REGION_0_CONTROL
{0x10804+4i} CBASS_FW_IDBG_AUTH_S_FW_REGION_0_PERMISSION_{i} (i=0..2) — The FW Region 0 Permission {i} Register defines the permissions for the target Idbg_auth.slv region 0 firewall.
  fields as CBASS_FW_ROM_FW_REGION_0_PERMISSION_0
0x10810 CBASS_FW_IDBG_AUTH_S_FW_REGION_0_START_ADDRESS_L access per field reset 0x44232000 — The FW Region 0 Start Address Low Register defines the start address bits 31 to 0 for the target Idbg_auth.slv region 0 firewall.
  fields as CBASS_FW_ROM_FW_REGION_0_START_ADDRESS_L
0x10814 CBASS_FW_IDBG_AUTH_S_FW_REGION_0_START_ADDRESS_H — The FW Region 0 Start Address High Register defines the start address bits 47 to 32 for the target Idbg_auth.slv region 0 firewall.
  fields as CBASS_FW_ROM_FW_REGION_0_START_ADDRESS_H
0x10818 CBASS_FW_IDBG_AUTH_S_FW_REGION_0_END_ADDRESS_L access per field reset 0x44232FFF — The FW Region 0 End Address Low Register defines the end address bits 31 to 0 to include for the target Idbg_auth.slv region 0 firewall.
  fields as CBASS_FW_ROM_FW_REGION_0_END_ADDRESS_L
0x1081C CBASS_FW_IDBG_AUTH_S_FW_REGION_0_END_ADDRESS_H — The FW Region 0 End Address High Register defines the end address bits 47 to 32 to include for the target Idbg_auth.slv region 0 firewall.
  fields as CBASS_FW_ROM_FW_REGION_0_END_ADDRESS_H
0x11800 CBASS_FW_ISECKEY_S_FW_REGION_0_CONTROL access not given — The FW Region 0 Control Register defines the control fields for the target Iseckey.slv region 0 firewall.
  fields as CBASS_FW_ROM_FW_REGION_0_CONTROL
{0x11804+4i} CBASS_FW_ISECKEY_S_FW_REGION_0_PERMISSION_{i} (i=0..2) — The FW Region 0 Permission {i} Register defines the permissions for the target Iseckey.slv region 0 firewall.
  fields as CBASS_FW_ROM_FW_REGION_0_PERMISSION_0
0x11810 CBASS_FW_ISECKEY_S_FW_REGION_0_START_ADDRESS_L access per field reset 0x44234000 — The FW Region 0 Start Address Low Register defines the start address bits 31 to 0 for the target Iseckey.slv region 0 firewall.
  fields as CBASS_FW_ROM_FW_REGION_0_START_ADDRESS_L
0x11814 CBASS_FW_ISECKEY_S_FW_REGION_0_START_ADDRESS_H — The FW Region 0 Start Address High Register defines the start address bits 47 to 32 for the target Iseckey.slv region 0 firewall.
  fields as CBASS_FW_ROM_FW_REGION_0_START_ADDRESS_H
0x11818 CBASS_FW_ISECKEY_S_FW_REGION_0_END_ADDRESS_L access per field reset 0x44237FFF — The FW Region 0 End Address Low Register defines the end address bits 31 to 0 to include for the target Iseckey.slv region 0 firewall.
  fields as CBASS_FW_ROM_FW_REGION_0_END_ADDRESS_L
0x1181C CBASS_FW_ISECKEY_S_FW_REGION_0_END_ADDRESS_H — The FW Region 0 End Address High Register defines the end address bits 47 to 32 to include for the target Iseckey.slv region 0 firewall.
  fields as CBASS_FW_ROM_FW_REGION_0_END_ADDRESS_H
0x11820 CBASS_FW_ISECKEY_S_FW_REGION_1_CONTROL access not given — The FW Region 1 Control Register defines the control fields for the target Iseckey.slv region 1 firewall.
  fields as CBASS_FW_ROM_FW_REGION_0_CONTROL
{0x11824+4i} CBASS_FW_ISECKEY_S_FW_REGION_1_PERMISSION_{i} (i=0..2) — The FW Region 1 Permission {i} Register defines the permissions for the target Iseckey.slv region 1 firewall.
  fields as CBASS_FW_ROM_FW_REGION_0_PERMISSION_0
0x11830 CBASS_FW_ISECKEY_S_FW_REGION_1_START_ADDRESS_L access per field — The FW Region 1 Start Address Low Register defines the start address bits 31 to 0 for the target Iseckey.slv region 1 firewall.
  fields as CBASS_FW_ROM_FW_REGION_0_START_ADDRESS_L
0x11834 CBASS_FW_ISECKEY_S_FW_REGION_1_START_ADDRESS_H — The FW Region 1 Start Address High Register defines the start address bits 47 to 32 for the target Iseckey.slv region 1 firewall.
  fields as CBASS_FW_ROM_FW_REGION_0_START_ADDRESS_H
0x11838 CBASS_FW_ISECKEY_S_FW_REGION_1_END_ADDRESS_L access per field reset 0xFFF — The FW Region 1 End Address Low Register defines the end address bits 31 to 0 to include for the target Iseckey.slv region 1 firewall.
  fields as CBASS_FW_ROM_FW_REGION_0_END_ADDRESS_L
0x1183C CBASS_FW_ISECKEY_S_FW_REGION_1_END_ADDRESS_H — The FW Region 1 End Address High Register defines the end address bits 47 to 32 to include for the target Iseckey.slv region 1 firewall.
  fields as CBASS_FW_ROM_FW_REGION_0_END_ADDRESS_H
0x14000 CBASS_FW_TIMER2_CFG_VBP_FW_REGION_0_CONTROL access not given — The FW Region 0 Control Register defines the control fields for the target Itimer3.timer_cfg_vbp region 0 firewall.
  fields as CBASS_FW_ROM_FW_REGION_0_CONTROL
{0x14004+4i} CBASS_FW_TIMER2_CFG_VBP_FW_REGION_0_PERMISSION_{i} (i=0..2) — The FW Region 0 Permission {i} Register defines the permissions for the target Itimer3.timer_cfg_vbp region 0 firewall.
  fields as CBASS_FW_ROM_FW_REGION_0_PERMISSION_0
0x14010 CBASS_FW_TIMER2_CFG_VBP_FW_REGION_0_START_ADDRESS_L access per field reset 0x44238000 — The FW Region 0 Start Address Low Register defines the start address bits 31 to 0 for the target Itimer3.timer_cfg_vbp region 0 firewall.
  fields as CBASS_FW_ROM_FW_REGION_0_START_ADDRESS_L
0x14014 CBASS_FW_TIMER2_CFG_VBP_FW_REGION_0_START_ADDRESS_H — The FW Region 0 Start Address High Register defines the start address bits 47 to 32 for the target Itimer3.timer_cfg_vbp region 0 firewall.
  fields as CBASS_FW_ROM_FW_REGION_0_START_ADDRESS_H
0x14018 CBASS_FW_TIMER2_CFG_VBP_FW_REGION_0_END_ADDRESS_L access per field reset 0x44238FFF — The FW Region 0 End Address Low Register defines the end address bits 31 to 0 to include for the target Itimer3.timer_cfg_vbp region 0 firewall.
  fields as CBASS_FW_ROM_FW_REGION_0_END_ADDRESS_L
0x1401C CBASS_FW_TIMER2_CFG_VBP_FW_REGION_0_END_ADDRESS_H — The FW Region 0 End Address High Register defines the end address bits 47 to 32 to include for the target Itimer3.timer_cfg_vbp region 0 firewall.
  fields as CBASS_FW_ROM_FW_REGION_0_END_ADDRESS_H
0x14400 CBASS_FW_TIMER3_CFG_VBP_FW_REGION_0_CONTROL access not given — The FW Region 0 Control Register defines the control fields for the target Itimer4.timer_cfg_vbp region 0 firewall.
  fields as CBASS_FW_ROM_FW_REGION_0_CONTROL
{0x14404+4i} CBASS_FW_TIMER3_CFG_VBP_FW_REGION_0_PERMISSION_{i} (i=0..2) — The FW Region 0 Permission {i} Register defines the permissions for the target Itimer4.timer_cfg_vbp region 0 firewall.
  fields as CBASS_FW_ROM_FW_REGION_0_PERMISSION_0
0x14410 CBASS_FW_TIMER3_CFG_VBP_FW_REGION_0_START_ADDRESS_L access per field reset 0x44239000 — The FW Region 0 Start Address Low Register defines the start address bits 31 to 0 for the target Itimer4.timer_cfg_vbp region 0 firewall.
  fields as CBASS_FW_ROM_FW_REGION_0_START_ADDRESS_L
0x14414 CBASS_FW_TIMER3_CFG_VBP_FW_REGION_0_START_ADDRESS_H — The FW Region 0 Start Address High Register defines the start address bits 47 to 32 for the target Itimer4.timer_cfg_vbp region 0 firewall.
  fields as CBASS_FW_ROM_FW_REGION_0_START_ADDRESS_H
0x14418 CBASS_FW_TIMER3_CFG_VBP_FW_REGION_0_END_ADDRESS_L access per field reset 0x44239FFF — The FW Region 0 End Address Low Register defines the end address bits 31 to 0 to include for the target Itimer4.timer_cfg_vbp region 0 firewall.
  fields as CBASS_FW_ROM_FW_REGION_0_END_ADDRESS_L
0x1441C CBASS_FW_TIMER3_CFG_VBP_FW_REGION_0_END_ADDRESS_H — The FW Region 0 End Address High Register defines the end address bits 47 to 32 to include for the target Itimer4.timer_cfg_vbp region 0 firewall.
  fields as CBASS_FW_ROM_FW_REGION_0_END_ADDRESS_H
0x16800 CBASS_FW_IAES_S_FW_REGION_0_CONTROL access not given — The FW Region 0 Control Register defines the control fields for the target Iaes.slv region 0 firewall.
  fields as CBASS_FW_ROM_FW_REGION_0_CONTROL
{0x16804+4i} CBASS_FW_IAES_S_FW_REGION_0_PERMISSION_{i} (i=0..2) — The FW Region 0 Permission {i} Register defines the permissions for the target Iaes.slv region 0 firewall.
  fields as CBASS_FW_ROM_FW_REGION_0_PERMISSION_0
0x16810 CBASS_FW_IAES_S_FW_REGION_0_START_ADDRESS_L access per field reset 0x4423C000 — The FW Region 0 Start Address Low Register defines the start address bits 31 to 0 for the target Iaes.slv region 0 firewall.
  fields as CBASS_FW_ROM_FW_REGION_0_START_ADDRESS_L
0x16814 CBASS_FW_IAES_S_FW_REGION_0_START_ADDRESS_H — The FW Region 0 Start Address High Register defines the start address bits 47 to 32 for the target Iaes.slv region 0 firewall.
  fields as CBASS_FW_ROM_FW_REGION_0_START_ADDRESS_H
0x16818 CBASS_FW_IAES_S_FW_REGION_0_END_ADDRESS_L access per field reset 0x4423DFFF — The FW Region 0 End Address Low Register defines the end address bits 31 to 0 to include for the target Iaes.slv region 0 firewall.
  fields as CBASS_FW_ROM_FW_REGION_0_END_ADDRESS_L
0x1681C CBASS_FW_IAES_S_FW_REGION_0_END_ADDRESS_H — The FW Region 0 End Address High Register defines the end address bits 47 to 32 to include for the target Iaes.slv region 0 firewall.
  fields as CBASS_FW_ROM_FW_REGION_0_END_ADDRESS_H
0x16820 CBASS_FW_IAES_S_FW_REGION_1_CONTROL access not given — The FW Region 1 Control Register defines the control fields for the target Iaes.slv region 1 firewall.
  fields as CBASS_FW_ROM_FW_REGION_0_CONTROL
{0x16824+4i} CBASS_FW_IAES_S_FW_REGION_1_PERMISSION_{i} (i=0..2) — The FW Region 1 Permission {i} Register defines the permissions for the target Iaes.slv region 1 firewall.
  fields as CBASS_FW_ROM_FW_REGION_0_PERMISSION_0
0x16830 CBASS_FW_IAES_S_FW_REGION_1_START_ADDRESS_L access per field — The FW Region 1 Start Address Low Register defines the start address bits 31 to 0 for the target Iaes.slv region 1 firewall.
  fields as CBASS_FW_ROM_FW_REGION_0_START_ADDRESS_L
0x16834 CBASS_FW_IAES_S_FW_REGION_1_START_ADDRESS_H — The FW Region 1 Start Address High Register defines the start address bits 47 to 32 for the target Iaes.slv region 1 firewall.
  fields as CBASS_FW_ROM_FW_REGION_0_START_ADDRESS_H
0x16838 CBASS_FW_IAES_S_FW_REGION_1_END_ADDRESS_L access per field reset 0xFFF — The FW Region 1 End Address Low Register defines the end address bits 31 to 0 to include for the target Iaes.slv region 1 firewall.
  fields as CBASS_FW_ROM_FW_REGION_0_END_ADDRESS_L
0x1683C CBASS_FW_IAES_S_FW_REGION_1_END_ADDRESS_H — The FW Region 1 End Address High Register defines the end address bits 47 to 32 to include for the target Iaes.slv region 1 firewall.
  fields as CBASS_FW_ROM_FW_REGION_0_END_ADDRESS_H
{0x1F800+0x20*i} CBASS_FW_SMS_DMSS_HSM_FW_REGION_{i}_CONTROL access not given (i=0..23) — The FW Region {i} Control Register defines the control fields for the target sms_dmss_hsm.slv region {i} firewall.
  fields as CBASS_FW_ROM_FW_REGION_0_CONTROL
{0x1F804+0x20*i} CBASS_FW_SMS_DMSS_HSM_FW_REGION_{i}_PERMISSION_0 (i=0..23) — The FW Region {i} Permission 0 Register defines the permissions for the target sms_dmss_hsm.slv region {i} firewall.
  fields as CBASS_FW_ROM_FW_REGION_0_PERMISSION_0
{0x1F808+0x20*i} CBASS_FW_SMS_DMSS_HSM_FW_REGION_{i}_PERMISSION_1 (i=0..23) — The FW Region {i} Permission 1 Register defines the permissions for the target sms_dmss_hsm.slv region {i} firewall.
  fields as CBASS_FW_ROM_FW_REGION_0_PERMISSION_0
{0x1F80C+0x20*i} CBASS_FW_SMS_DMSS_HSM_FW_REGION_{i}_PERMISSION_2 (i=0..23) — The FW Region {i} Permission 2 Register defines the permissions for the target sms_dmss_hsm.slv region {i} firewall.
  fields as CBASS_FW_ROM_FW_REGION_0_PERMISSION_0
0x1F810 CBASS_FW_SMS_DMSS_HSM_FW_REGION_0_START_ADDRESS_L access per field reset 0x44800000 — The FW Region 0 Start Address Low Register defines the start address bits 31 to 0 for the target sms_dmss_hsm.slv region 0 firewall.
  fields as CBASS_FW_ROM_FW_REGION_0_START_ADDRESS_L
{0x1F814+0x20*i} CBASS_FW_SMS_DMSS_HSM_FW_REGION_{i}_START_ADDRESS_H (i=0..23) — The FW Region {i} Start Address High Register defines the start address bits 47 to 32 for the target sms_dmss_hsm.slv region {i} firewall.
  fields as CBASS_FW_ROM_FW_REGION_0_START_ADDRESS_H
0x1F818 CBASS_FW_SMS_DMSS_HSM_FW_REGION_0_END_ADDRESS_L access per field reset 0x44FFFFFF — The FW Region 0 End Address Low Register defines the end address bits 31 to 0 to include for the target sms_dmss_hsm.slv region 0 firewall.
  fields as CBASS_FW_ROM_FW_REGION_0_END_ADDRESS_L
{0x1F81C+0x20*i} CBASS_FW_SMS_DMSS_HSM_FW_REGION_{i}_END_ADDRESS_H (i=0..23) — The FW Region {i} End Address High Register defines the end address bits 47 to 32 to include for the target sms_dmss_hsm.slv region {i} firewall.
  fields as CBASS_FW_ROM_FW_REGION_0_END_ADDRESS_H
0x1F830 CBASS_FW_SMS_DMSS_HSM_FW_REGION_1_START_ADDRESS_L access per field reset 0x43702000 — The FW Region 1 Start Address Low Register defines the start address bits 31 to 0 for the target sms_dmss_hsm.slv region 1 firewall.
  fields as CBASS_FW_ROM_FW_REGION_0_START_ADDRESS_L
0x1F838 CBASS_FW_SMS_DMSS_HSM_FW_REGION_1_END_ADDRESS_L access per field reset 0x43702FFF — The FW Region 1 End Address Low Register defines the end address bits 31 to 0 to include for the target sms_dmss_hsm.slv region 1 firewall.
  fields as CBASS_FW_ROM_FW_REGION_0_END_ADDRESS_L
{0x1F810+0x20*i} CBASS_FW_SMS_DMSS_HSM_FW_REGION_{i}_START_ADDRESS_L access per field (i=2..23) — The FW Region {i} Start Address Low Register defines the start address bits 31 to 0 for the target sms_dmss_hsm.slv region {i} firewall.
  fields as CBASS_FW_ROM_FW_REGION_0_START_ADDRESS_L
{0x1F818+0x20*i} CBASS_FW_SMS_DMSS_HSM_FW_REGION_{i}_END_ADDRESS_L access per field reset 0xFFF (i=2..23) — The FW Region {i} End Address Low Register defines the end address bits 31 to 0 to include for the target sms_dmss_hsm.slv region {i} firewall.
  fields as CBASS_FW_ROM_FW_REGION_0_END_ADDRESS_L
{0x1FC00+0x20*i} CBASS_FW_IFWMGR_M_FW_REGION_{i}_CONTROL access not given (i=0..7) — The FW Region {i} Control Register defines the control fields for the target Ifwmgr_int.slv region {i} firewall.
  fields as CBASS_FW_ROM_FW_REGION_0_CONTROL
{0x1FC04+0x20*i} CBASS_FW_IFWMGR_M_FW_REGION_{i}_PERMISSION_0 (i=0..7) — The FW Region {i} Permission 0 Register defines the permissions for the target Ifwmgr_int.slv region {i} firewall.
  fields as CBASS_FW_ROM_FW_REGION_0_PERMISSION_0
{0x1FC08+0x20*i} CBASS_FW_IFWMGR_M_FW_REGION_{i}_PERMISSION_1 (i=0..7) — The FW Region {i} Permission 1 Register defines the permissions for the target Ifwmgr_int.slv region {i} firewall.
  fields as CBASS_FW_ROM_FW_REGION_0_PERMISSION_0
{0x1FC0C+0x20*i} CBASS_FW_IFWMGR_M_FW_REGION_{i}_PERMISSION_2 (i=0..7) — The FW Region {i} Permission 2 Register defines the permissions for the target Ifwmgr_int.slv region {i} firewall.
  fields as CBASS_FW_ROM_FW_REGION_0_PERMISSION_0
0x1FC10 CBASS_FW_IFWMGR_M_FW_REGION_0_START_ADDRESS_L access per field reset 0x45000000 — The FW Region 0 Start Address Low Register defines the start address bits 31 to 0 for the target Ifwmgr_int.slv region 0 firewall.
  fields as CBASS_FW_ROM_FW_REGION_0_START_ADDRESS_L
{0x1FC14+0x20*i} CBASS_FW_IFWMGR_M_FW_REGION_{i}_START_ADDRESS_H (i=0..7) — The FW Region {i} Start Address High Register defines the start address bits 47 to 32 for the target Ifwmgr_int.slv region {i} firewall.
  fields as CBASS_FW_ROM_FW_REGION_0_START_ADDRESS_H
0x1FC18 CBASS_FW_IFWMGR_M_FW_REGION_0_END_ADDRESS_L access per field reset 0x45FFFFFF — The FW Region 0 End Address Low Register defines the end address bits 31 to 0 to include for the target Ifwmgr_int.slv region 0 firewall.
  fields as CBASS_FW_ROM_FW_REGION_0_END_ADDRESS_L
{0x1FC1C+0x20*i} CBASS_FW_IFWMGR_M_FW_REGION_{i}_END_ADDRESS_H (i=0..7) — The FW Region {i} End Address High Register defines the end address bits 47 to 32 to include for the target Ifwmgr_int.slv region {i} firewall.
  fields as CBASS_FW_ROM_FW_REGION_0_END_ADDRESS_H
{0x1FC10+0x20*i} CBASS_FW_IFWMGR_M_FW_REGION_{i}_START_ADDRESS_L access per field (i=1..7) — The FW Region {i} Start Address Low Register defines the start address bits 31 to 0 for the target Ifwmgr_int.slv region {i} firewall.
  fields as CBASS_FW_ROM_FW_REGION_0_START_ADDRESS_L
{0x1FC18+0x20*i} CBASS_FW_IFWMGR_M_FW_REGION_{i}_END_ADDRESS_L access per field reset 0xFFF (i=1..7) — The FW Region {i} End Address Low Register defines the end address bits 31 to 0 to include for the target Ifwmgr_int.slv region {i} firewall.
  fields as CBASS_FW_ROM_FW_REGION_0_END_ADDRESS_L
